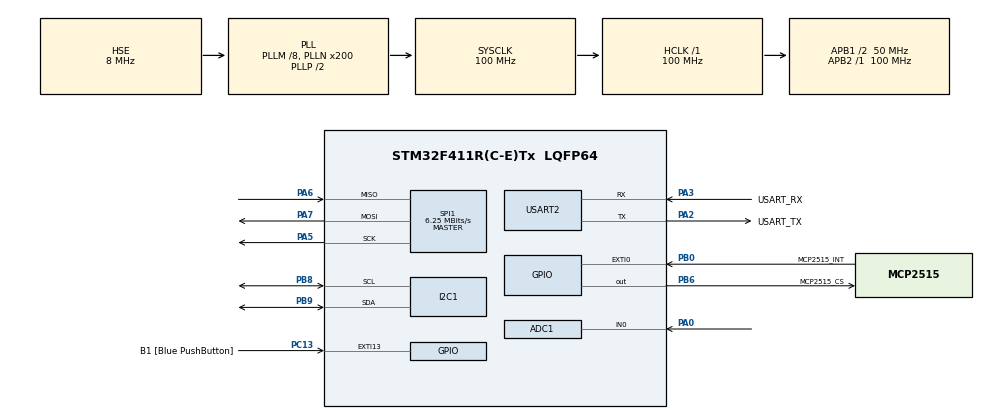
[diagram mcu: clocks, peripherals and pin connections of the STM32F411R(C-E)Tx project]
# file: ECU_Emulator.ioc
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ADC1.Channel-0\#ChannelRegularConversion=ADC_CHANNEL_0
ADC1.NbrOfConversionFlag=1
ADC1.Rank-0\#ChannelRegularConversion=1
ADC1.SamplingTime-0\#ChannelRegularConversion=ADC_SAMPLETIME_3CYCLES
ADC1.master=1
FREERTOS.INCLUDE_vTaskDelayUntil=1
FREERTOS.Tasks01=defaultTask,0,512,StartDefaultTask,Default,NULL,Dynamic,NULL,NULL
FREERTOS.configCHECK_FOR_STACK_OVERFLOW=2
FREERTOS.configMAX_PRIORITIES=8
FREERTOS.configMINIMAL_STACK_SIZE=512
Mcu.Family=STM32F4
Mcu.Name=STM32F411R(C-E)Tx
Mcu.Package=LQFP64
NVIC.EXTI15_10_IRQn=true\:5\:0\:true\:false\:true\:true\:true\:true\:true
NVIC.PriorityGroup=NVIC_PRIORITYGROUP_4
NVIC.TIM4_IRQn=true\:15\:0\:false\:false\:true\:false\:false\:true\:true
NVIC.TimeBase=TIM4_IRQn
NVIC.TimeBaseIP=TIM4
PA0-WKUP.Signal=ADCx_IN0
PA13.GPIO_Label=TMS
PA13.Mode=Serial_Wire
PA13.Signal=SYS_JTMS-SWDIO
PA14.GPIO_Label=TCK
PA14.Mode=Serial_Wire
PA14.Signal=SYS_JTCK-SWCLK
PA2.GPIO_Label=USART_TX
PA2.Mode=Asynchronous
PA2.Signal=USART2_TX
PA3.GPIO_Label=USART_RX
PA3.Mode=Asynchronous
PA3.Signal=USART2_RX
PA5.Mode=Full_Duplex_Master
PA5.Signal=SPI1_SCK
PA6.Mode=Full_Duplex_Master
PA6.Signal=SPI1_MISO
PA7.Mode=Full_Duplex_Master
PA7.Signal=SPI1_MOSI
PB0.GPIO_Label=MCP2515_INT
PB0.GPIO_ModeDefaultEXTI=GPIO_MODE_IT_FALLING
PB0.GPIO_PuPd=GPIO_PULLUP
PB0.Signal=GPXTI0
PB3.GPIO_Label=SWO
PB3.Signal=SYS_JTDO-SWO
PB6.GPIO_Label=MCP2515_CS
PB6.GPIO_Speed=GPIO_SPEED_FREQ_HIGH
PB6.PinState=GPIO_PIN_SET
PB6.Signal=GPIO_Output
PB8.Mode=I2C
PB8.Signal=I2C1_SCL
PB9.Mode=I2C
PB9.Signal=I2C1_SDA
PC13-ANTI_TAMP.GPIO_Label=B1 [Blue PushButton]
PC13-ANTI_TAMP.GPIO_ModeDefaultEXTI=GPIO_MODE_IT_FALLING
PC13-ANTI_TAMP.Signal=GPXTI13
PC14-OSC32_IN.Mode=LSE-External-Oscillator
PC14-OSC32_IN.Signal=RCC_OSC32_IN
PC15-OSC32_OUT.Mode=LSE-External-Oscillator
PC15-OSC32_OUT.Signal=RCC_OSC32_OUT
PH0\ -\ OSC_IN.Mode=HSE-External-Clock-Source
PH0\ -\ OSC_IN.Signal=RCC_OSC_IN
PH1\ -\ OSC_OUT.Mode=HSE-External-Clock-Source
PH1\ -\ OSC_OUT.Signal=RCC_OSC_OUT
ProjectManager.HeapSize=0x200
ProjectManager.StackSize=0x400
ProjectManager.TargetToolchain=STM32CubeIDE
RCC.48MHZClocksFreq_Value=50000000
RCC.AHBFreq_Value=100000000
RCC.APB1CLKDivider=RCC_HCLK_DIV2
RCC.APB1Freq_Value=50000000
RCC.APB1TimFreq_Value=100000000
RCC.APB2Freq_Value=100000000
RCC.APB2TimFreq_Value=100000000
RCC.CortexFreq_Value=100000000
RCC.FLatency-AdvancedSettings=FLASH_LATENCY_3
RCC.HCLKFreq_Value=100000000
RCC.HSE_VALUE=8000000
RCC.HSI_VALUE=16000000
RCC.PLLM=8
RCC.PLLN=200
RCC.PLLSourceVirtual=RCC_PLLSOURCE_HSE
RCC.SYSCLKFreq_VALUE=100000000
RCC.SYSCLKSource=RCC_SYSCLKSOURCE_PLLCLK
RCC.VCOOutputFreq_Value=200000000
SH.ADCx_IN0.0=ADC1_IN0,IN0
SPI1.BaudRatePrescaler=SPI_BAUDRATEPRESCALER_16
SPI1.CalculateBaudRate=6.25 MBits/s
SPI1.Direction=SPI_DIRECTION_2LINES
SPI1.Mode=SPI_MODE_MASTER
SPI1.VirtualType=VM_MASTER
USART2.VirtualMode=VM_ASYNC
VP_FREERTOS_VS_CMSIS_V1.Mode=CMSIS_V1
VP_SYS_VS_tim4.Mode=TIM4
board=NUCLEO-F411RE

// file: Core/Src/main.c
/* USER CODE BEGIN Header */
// : - : Main program body
/* USER CODE END Header */
#include "main.h"
#include "cmsis_os.h"

/* USER CODE BEGIN Includes */
#include "app_tasks_ecu.h"
#include "FreeRTOS.h"
#include "task.h"
/* USER CODE END Includes */

ADC_HandleTypeDef hadc1;

I2C_HandleTypeDef hi2c1;

SPI_HandleTypeDef hspi1;

UART_HandleTypeDef huart2;

osThreadId defaultTaskHandle;

void SystemClock_Config(void);
static void MX_GPIO_Init(void);
static void MX_USART2_UART_Init(void);
static void MX_SPI1_Init(void);
static void MX_I2C1_Init(void);
static void MX_ADC1_Init(void);
void StartDefaultTask(void const * argument);

int main(void)
{

  /* MCU Configuration--------------------------------------------------------*/

  /* Reset of all peripherals, Initializes the Flash interface and the Systick. */
  HAL_Init();

  /* Configure the system clock */
  SystemClock_Config();

  /* Initialize all configured peripherals */
  MX_GPIO_Init();
  MX_USART2_UART_Init();
  MX_SPI1_Init();
  MX_I2C1_Init();
  MX_ADC1_Init();
  /* USER CODE BEGIN 2 */

  {
      const char boot_msg[] = "\r\n=== IntelliOBD ECU Boot ===\r\n";
      HAL_UART_Transmit(&huart2, (uint8_t*)boot_msg, sizeof(boot_msg)-1, HAL_MAX_DELAY);
  }
  /* USER CODE END 2 */

  /* Create the thread(s) */
  /* definition and creation of defaultTask */
  osThreadDef(defaultTask, StartDefaultTask, osPriorityNormal, 0, 512);
  defaultTaskHandle = osThreadCreate(osThread(defaultTask), NULL);

  /* Start scheduler */
  osKernelStart();

  /* We should never get here as control is now taken by the scheduler */

  /* Infinite loop */
  while (1)
  {

  }
}

void SystemClock_Config(void)
{
  RCC_OscInitTypeDef RCC_OscInitStruct = {0};
  RCC_ClkInitTypeDef RCC_ClkInitStruct = {0};

  /** Configure the main internal regulator output voltage
  */
  __HAL_RCC_PWR_CLK_ENABLE();
  __HAL_PWR_VOLTAGESCALING_CONFIG(PWR_REGULATOR_VOLTAGE_SCALE1);

  /** Initializes the RCC Oscillators according to the specified parameters
  * in the RCC_OscInitTypeDef structure.
  */
  RCC_OscInitStruct.OscillatorType = RCC_OSCILLATORTYPE_HSE;
  RCC_OscInitStruct.HSEState = RCC_HSE_BYPASS;
  RCC_OscInitStruct.PLL.PLLState = RCC_PLL_ON;
  RCC_OscInitStruct.PLL.PLLSource = RCC_PLLSOURCE_HSE;
  RCC_OscInitStruct.PLL.PLLM = 8;
  RCC_OscInitStruct.PLL.PLLN = 200;
  RCC_OscInitStruct.PLL.PLLP = RCC_PLLP_DIV2;
  RCC_OscInitStruct.PLL.PLLQ = 4;
  if (HAL_RCC_OscConfig(&RCC_OscInitStruct) != HAL_OK)
  {
    Error_Handler();
  }

  /** Initializes the CPU, AHB and APB buses clocks
  */
  RCC_ClkInitStruct.ClockType = RCC_CLOCKTYPE_HCLK|RCC_CLOCKTYPE_SYSCLK
                              |RCC_CLOCKTYPE_PCLK1|RCC_CLOCKTYPE_PCLK2;
  RCC_ClkInitStruct.SYSCLKSource = RCC_SYSCLKSOURCE_PLLCLK;
  RCC_ClkInitStruct.AHBCLKDivider = RCC_SYSCLK_DIV1;
  RCC_ClkInitStruct.APB1CLKDivider = RCC_HCLK_DIV2;
  RCC_ClkInitStruct.APB2CLKDivider = RCC_HCLK_DIV1;

  if (HAL_RCC_ClockConfig(&RCC_ClkInitStruct, FLASH_LATENCY_3) != HAL_OK)
  {
    Error_Handler();
  }
}

static void MX_ADC1_Init(void)
{

  ADC_ChannelConfTypeDef sConfig = {0};

  /** Configure the global features of the ADC (Clock, Resolution, Data Alignment and number of conversion)
  */
  hadc1.Instance = ADC1;
  hadc1.Init.ClockPrescaler = ADC_CLOCK_SYNC_PCLK_DIV4;
  hadc1.Init.Resolution = ADC_RESOLUTION_12B;
  hadc1.Init.ScanConvMode = DISABLE;
  hadc1.Init.ContinuousConvMode = DISABLE;
  hadc1.Init.DiscontinuousConvMode = DISABLE;
  hadc1.Init.ExternalTrigConvEdge = ADC_EXTERNALTRIGCONVEDGE_NONE;
  hadc1.Init.ExternalTrigConv = ADC_SOFTWARE_START;
  hadc1.Init.DataAlign = ADC_DATAALIGN_RIGHT;
  hadc1.Init.NbrOfConversion = 1;
  hadc1.Init.DMAContinuousRequests = DISABLE;
  hadc1.Init.EOCSelection = ADC_EOC_SINGLE_CONV;
  if (HAL_ADC_Init(&hadc1) != HAL_OK)
  {
    Error_Handler();
  }

  /** Configure for the selected ADC regular channel its corresponding rank in the sequencer and its sample time.
  */
  sConfig.Channel = ADC_CHANNEL_0;
  sConfig.Rank = 1;
  sConfig.SamplingTime = ADC_SAMPLETIME_3CYCLES;
  if (HAL_ADC_ConfigChannel(&hadc1, &sConfig) != HAL_OK)
  {
    Error_Handler();
  }

}

static void MX_I2C1_Init(void)
{

  hi2c1.Instance = I2C1;
  hi2c1.Init.ClockSpeed = 100000;
  hi2c1.Init.DutyCycle = I2C_DUTYCYCLE_2;
  hi2c1.Init.OwnAddress1 = 0;
  hi2c1.Init.AddressingMode = I2C_ADDRESSINGMODE_7BIT;
  hi2c1.Init.DualAddressMode = I2C_DUALADDRESS_DISABLE;
  hi2c1.Init.OwnAddress2 = 0;
  hi2c1.Init.GeneralCallMode = I2C_GENERALCALL_DISABLE;
  hi2c1.Init.NoStretchMode = I2C_NOSTRETCH_DISABLE;
  if (HAL_I2C_Init(&hi2c1) != HAL_OK)
  {
    Error_Handler();
  }

}

static void MX_SPI1_Init(void)
{

  /* SPI1 parameter configuration*/
  hspi1.Instance = SPI1;
  hspi1.Init.Mode = SPI_MODE_MASTER;
  hspi1.Init.Direction = SPI_DIRECTION_2LINES;
  hspi1.Init.DataSize = SPI_DATASIZE_8BIT;
  hspi1.Init.CLKPolarity = SPI_POLARITY_LOW;
  hspi1.Init.CLKPhase = SPI_PHASE_1EDGE;
  hspi1.Init.NSS = SPI_NSS_SOFT;
  hspi1.Init.BaudRatePrescaler = SPI_BAUDRATEPRESCALER_16;
  hspi1.Init.FirstBit = SPI_FIRSTBIT_MSB;
  hspi1.Init.TIMode = SPI_TIMODE_DISABLE;
  hspi1.Init.CRCCalculation = SPI_CRCCALCULATION_DISABLE;
  hspi1.Init.CRCPolynomial = 10;
  if (HAL_SPI_Init(&hspi1) != HAL_OK)
  {
    Error_Handler();
  }

}

static void MX_USART2_UART_Init(void)
{

  huart2.Instance = USART2;
  huart2.Init.BaudRate = 115200;
  huart2.Init.WordLength = UART_WORDLENGTH_8B;
  huart2.Init.StopBits = UART_STOPBITS_1;
  huart2.Init.Parity = UART_PARITY_NONE;
  huart2.Init.Mode = UART_MODE_TX_RX;
  huart2.Init.HwFlowCtl = UART_HWCONTROL_NONE;
  huart2.Init.OverSampling = UART_OVERSAMPLING_16;
  if (HAL_UART_Init(&huart2) != HAL_OK)
  {
    Error_Handler();
  }

}

static void MX_GPIO_Init(void)
{
  GPIO_InitTypeDef GPIO_InitStruct = {0};

  /* GPIO Ports Clock Enable */
  __HAL_RCC_GPIOC_CLK_ENABLE();
  __HAL_RCC_GPIOH_CLK_ENABLE();
  __HAL_RCC_GPIOA_CLK_ENABLE();
  __HAL_RCC_GPIOB_CLK_ENABLE();

  /*Configure GPIO pin Output Level */
  HAL_GPIO_WritePin(MCP2515_CS_GPIO_Port, MCP2515_CS_Pin, GPIO_PIN_SET);

  /*Configure GPIO pin : B1_Pin */
  GPIO_InitStruct.Pin = B1_Pin;
  GPIO_InitStruct.Mode = GPIO_MODE_IT_FALLING;
  GPIO_InitStruct.Pull = GPIO_NOPULL;
  HAL_GPIO_Init(B1_GPIO_Port, &GPIO_InitStruct);

  /*Configure GPIO pin : MCP2515_INT_Pin */
  GPIO_InitStruct.Pin = MCP2515_INT_Pin;
  GPIO_InitStruct.Mode = GPIO_MODE_IT_FALLING;
  GPIO_InitStruct.Pull = GPIO_PULLUP;
  HAL_GPIO_Init(MCP2515_INT_GPIO_Port, &GPIO_InitStruct);

  /*Configure GPIO pin : MCP2515_CS_Pin */
  GPIO_InitStruct.Pin = MCP2515_CS_Pin;
  GPIO_InitStruct.Mode = GPIO_MODE_OUTPUT_PP;
  GPIO_InitStruct.Pull = GPIO_NOPULL;
  GPIO_InitStruct.Speed = GPIO_SPEED_FREQ_HIGH;
  HAL_GPIO_Init(MCP2515_CS_GPIO_Port, &GPIO_InitStruct);

  /* EXTI interrupt init*/
  HAL_NVIC_SetPriority(EXTI15_10_IRQn, 5, 0);
  HAL_NVIC_EnableIRQ(EXTI15_10_IRQn);

  /* USER CODE BEGIN MX_GPIO_Init_2 */

  HAL_NVIC_SetPriority(EXTI0_IRQn, 6, 0);
  HAL_NVIC_EnableIRQ(EXTI0_IRQn);
  /* USER CODE END MX_GPIO_Init_2 */
}

/* USER CODE BEGIN 4 */

// Printf retarget: syscalls.c'deki _write() bu fonksiyonu çağırır
int __io_putchar(int ch)
{
    uint8_t c = (uint8_t)ch;
    HAL_UART_Transmit(&huart2, &c, 1, HAL_MAX_DELAY);
    return ch;
}

/* USER CODE END 4 */

/* USER CODE BEGIN Header_StartDefaultTask */
// Bootstrap task — ECU alt-sistem task'larını oluşturur ve kendini siler.
/* USER CODE END Header_StartDefaultTask */
void StartDefaultTask(void const * argument)
{
  /* USER CODE BEGIN 5 */
  (void)argument;

  AppTasks_ECU_Init(&hspi1, &huart2, &hi2c1);

  vTaskDelete(NULL);
  /* USER CODE END 5 */
}

void HAL_TIM_PeriodElapsedCallback(TIM_HandleTypeDef *htim)
{
  if (htim->Instance == TIM4)
  {
    HAL_IncTick();
  }
}

void Error_Handler(void)
{
  __disable_irq();
  while (1)
  {
  }
}

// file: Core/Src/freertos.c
/* USER CODE BEGIN Header */

/* USER CODE END Header */

#include "FreeRTOS.h"
#include "task.h"
#include "main.h"

/* GetIdleTaskMemory prototype (linked to static allocation support) */
void vApplicationGetIdleTaskMemory( StaticTask_t **ppxIdleTaskTCBBuffer, StackType_t **ppxIdleTaskStackBuffer, uint32_t *pulIdleTaskStackSize );

/* Hook prototypes */
void vApplicationStackOverflowHook(xTaskHandle xTask, signed char *pcTaskName);

/* USER CODE BEGIN 4 */
__weak void vApplicationStackOverflowHook(xTaskHandle xTask, signed char *pcTaskName)
{

   __disable_irq();
   while(1) {

   }
}
/* USER CODE END 4 */

/* USER CODE BEGIN GET_IDLE_TASK_MEMORY */
static StaticTask_t xIdleTaskTCBBuffer;
static StackType_t xIdleStack[configMINIMAL_STACK_SIZE];

void vApplicationGetIdleTaskMemory( StaticTask_t **ppxIdleTaskTCBBuffer, StackType_t **ppxIdleTaskStackBuffer, uint32_t *pulIdleTaskStackSize )
{
  *ppxIdleTaskTCBBuffer = &xIdleTaskTCBBuffer;
  *ppxIdleTaskStackBuffer = &xIdleStack[0];
  *pulIdleTaskStackSize = configMINIMAL_STACK_SIZE;

}
/* USER CODE END GET_IDLE_TASK_MEMORY */
